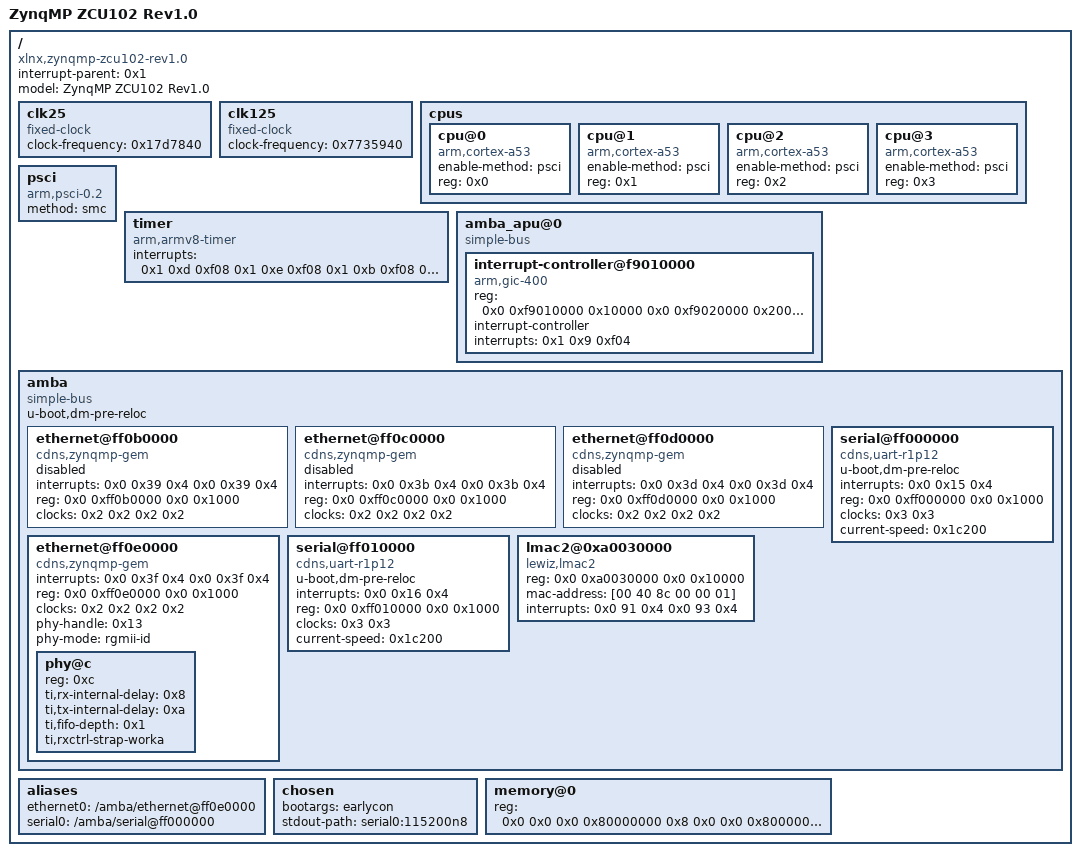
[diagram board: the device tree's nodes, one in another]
/dts-v1/;

/ {
	compatible = "xlnx,zynqmp-zcu102-rev1.0", "xlnx,zynqmp-zcu102", "xlnx,zynqmp";
	#address-cells = <0x2>;
	#size-cells = <0x2>;
	interrupt-parent = <0x1>;
	model = "ZynqMP ZCU102 Rev1.0";

	clk25 {
		compatible = "fixed-clock";
		#clock-cells = <0x0>;
		clock-frequency = <0x17d7840>;
		linux,phandle = <0x3>;
		phandle = <0x3>;
	};

	clk125 {
		compatible = "fixed-clock";
		#clock-cells = <0x0>;
		clock-frequency = <0x7735940>;
		linux,phandle = <0x2>;
		phandle = <0x2>;
	};

	cpus {
		#address-cells = <0x1>;
		#size-cells = <0x0>;

		cpu@0 {
			compatible = "arm,cortex-a53", "arm,armv8";
			device_type = "cpu";
			enable-method = "psci";
			reg = <0x0>;
		};

		cpu@1 {
			compatible = "arm,cortex-a53", "arm,armv8";
			device_type = "cpu";
			enable-method = "psci";
			reg = <0x1>;
		};

		cpu@2 {
			compatible = "arm,cortex-a53", "arm,armv8";
			device_type = "cpu";
			enable-method = "psci";
			reg = <0x2>;
		};

		cpu@3 {
			compatible = "arm,cortex-a53", "arm,armv8";
			device_type = "cpu";
			enable-method = "psci";
			reg = <0x3>;
		};
	};

	psci {
		compatible = "arm,psci-0.2";
		method = "smc";
	};

	timer {
		compatible = "arm,armv8-timer";
		interrupts = <0x1 0xd 0xf08 0x1 0xe 0xf08 0x1 0xb 0xf08 0x1 0xa 0xf08>;
	};

	amba_apu@0 {
		compatible = "simple-bus";
		#address-cells = <0x2>;
		#size-cells = <0x1>;
		ranges = <0x0 0x0 0x0 0x0 0xffffffff>;

		interrupt-controller@f9010000 {
			compatible = "arm,gic-400", "arm,cortex-a15-gic";
			#interrupt-cells = <0x3>;
			reg = <0x0 0xf9010000 0x10000 0x0 0xf9020000 0x20000 0x0 0xf9040000 0x20000 0x0 0xf9060000 0x20000>;
			interrupt-controller;
			interrupts = <0x1 0x9 0xf04>;
			linux,phandle = <0x1>;
			phandle = <0x1>;
		};
	};

	amba {
		compatible = "simple-bus";
		u-boot,dm-pre-reloc;
		#address-cells = <0x2>;
		#size-cells = <0x2>;
		ranges;

		ethernet@ff0b0000 {
			compatible = "cdns,zynqmp-gem", "cdns,gem";
			status = "disabled";
			interrupts = <0x0 0x39 0x4 0x0 0x39 0x4>;
			reg = <0x0 0xff0b0000 0x0 0x1000>;
			clock-names = "pclk", "hclk", "tx_clk", "rx_clk";
			#address-cells = <0x1>;
			#size-cells = <0x0>;
			#stream-id-cells = <0x1>;
			clocks = <0x2 0x2 0x2 0x2>;
		};

		ethernet@ff0c0000 {
			compatible = "cdns,zynqmp-gem", "cdns,gem";
			status = "disabled";
			interrupts = <0x0 0x3b 0x4 0x0 0x3b 0x4>;
			reg = <0x0 0xff0c0000 0x0 0x1000>;
			clock-names = "pclk", "hclk", "tx_clk", "rx_clk";
			#address-cells = <0x1>;
			#size-cells = <0x0>;
			#stream-id-cells = <0x1>;
			clocks = <0x2 0x2 0x2 0x2>;
		};

		ethernet@ff0d0000 {
			compatible = "cdns,zynqmp-gem", "cdns,gem";
			status = "disabled";
			interrupts = <0x0 0x3d 0x4 0x0 0x3d 0x4>;
			reg = <0x0 0xff0d0000 0x0 0x1000>;
			clock-names = "pclk", "hclk", "tx_clk", "rx_clk";
			#address-cells = <0x1>;
			#size-cells = <0x0>;
			#stream-id-cells = <0x1>;
			clocks = <0x2 0x2 0x2 0x2>;
		};

		ethernet@ff0e0000 {
			compatible = "cdns,zynqmp-gem", "cdns,gem";
			status = "okay";
			interrupts = <0x0 0x3f 0x4 0x0 0x3f 0x4>;
			reg = <0x0 0xff0e0000 0x0 0x1000>;
			clock-names = "pclk", "hclk", "tx_clk", "rx_clk";
			#address-cells = <0x1>;
			#size-cells = <0x0>;
			#stream-id-cells = <0x1>;
			clocks = <0x2 0x2 0x2 0x2>;
			phy-handle = <0x13>;
			phy-mode = "rgmii-id";

			phy@c {
				reg = <0xc>;
				ti,rx-internal-delay = <0x8>;
				ti,tx-internal-delay = <0xa>;
				ti,fifo-depth = <0x1>;
				ti,rxctrl-strap-worka;
				phandle = <0x13>;
			};
		};

		serial@ff000000 {
			u-boot,dm-pre-reloc;
			compatible = "cdns,uart-r1p12", "xlnx,xuartps";
			status = "okay";
			interrupts = <0x0 0x15 0x4>;
			reg = <0x0 0xff000000 0x0 0x1000>;
			clock-names = "uart_clk", "pclk";
			clocks = <0x3 0x3>;
			current-speed = <0x1c200>;
		};

		serial@ff010000 {
			u-boot,dm-pre-reloc;
			compatible = "cdns,uart-r1p12", "xlnx,xuartps";
			status = "okay";
			interrupts = <0x0 0x16 0x4>;
			reg = <0x0 0xff010000 0x0 0x1000>;
			clock-names = "uart_clk", "pclk";
			clocks = <0x3 0x3>;
			current-speed = <0x1c200>;
		};

		lmac2@0xa0030000 {
			compatible = "lewiz,lmac2";
			reg = <0x0 0xa0030000 0x0 0x10000>;
			mac-address = [00 40 8c 00 00 01];
			interrupt-names = "tx", "rx";
			interrupts = <0x0 91 0x4 0x0 93 0x4>;
		};
	};

	aliases {
		ethernet0 = "/amba/ethernet@ff0e0000";
		serial0 = "/amba/serial@ff000000";
	};

	chosen {
		bootargs = "earlycon";
		stdout-path = "serial0:115200n8";
	};

	memory@0 {
		device_type = "memory";
		reg = <0x0 0x0 0x0 0x80000000 0x8 0x0 0x0 0x80000000>;
	};
};
